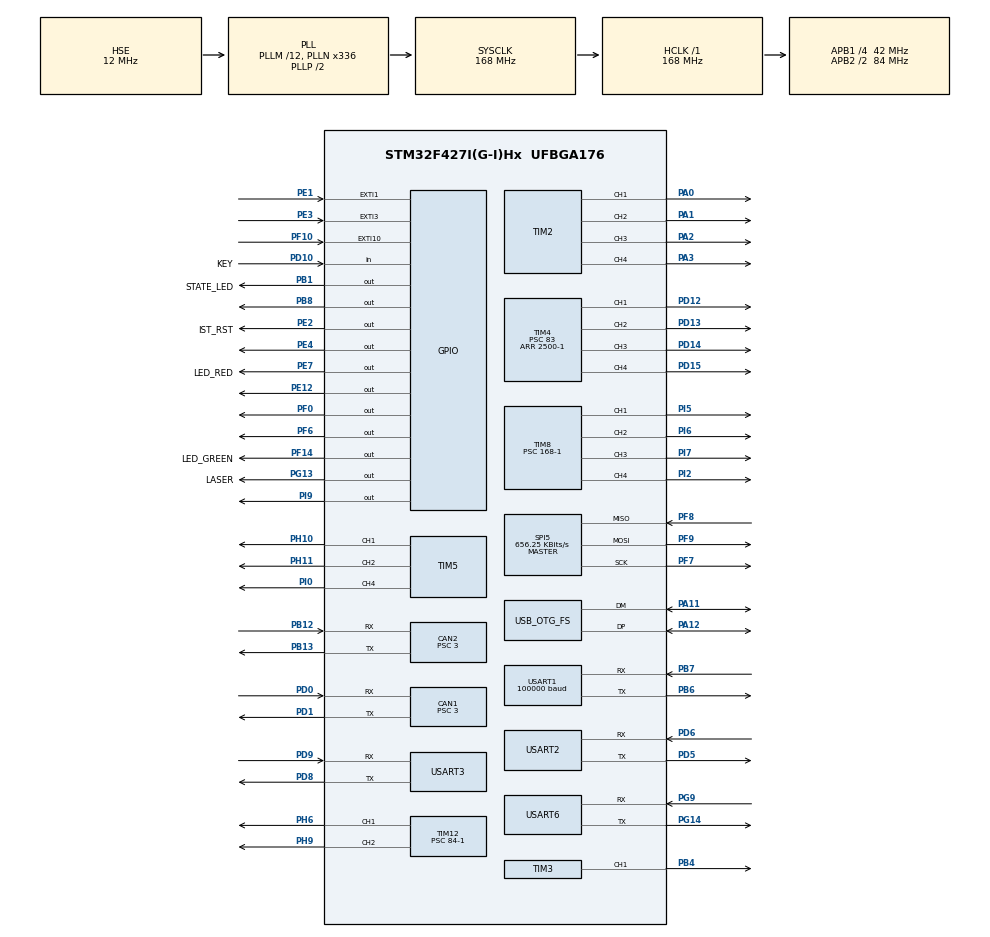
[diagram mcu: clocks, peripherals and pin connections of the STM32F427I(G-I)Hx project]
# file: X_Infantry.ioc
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CAN1.ABOM=DISABLE
CAN1.BS1=CAN_BS1_9TQ
CAN1.BS2=CAN_BS2_4TQ
CAN1.CalculateTimeBit=1000
CAN1.CalculateTimeQuantum=71.42857142857143
CAN1.Mode=CAN_MODE_NORMAL
CAN1.Prescaler=3
CAN1.SJW=CAN_SJW_1TQ
CAN1.TXFP=DISABLE
CAN2.ABOM=DISABLE
CAN2.BS1=CAN_BS1_9TQ
CAN2.BS2=CAN_BS2_4TQ
CAN2.CalculateTimeBit=1000
CAN2.CalculateTimeQuantum=71.42857142857143
CAN2.Mode=CAN_MODE_NORMAL
CAN2.Prescaler=3
CAN2.TXFP=DISABLE
Dma.Request0=USART1_RX
Dma.Request1=USART3_RX
Dma.USART1_RX.0.Direction=DMA_PERIPH_TO_MEMORY
Dma.USART1_RX.0.FIFOMode=DMA_FIFOMODE_DISABLE
Dma.USART1_RX.0.Instance=DMA2_Stream2
Dma.USART1_RX.0.MemDataAlignment=DMA_MDATAALIGN_BYTE
Dma.USART1_RX.0.MemInc=DMA_MINC_ENABLE
Dma.USART1_RX.0.Mode=DMA_NORMAL
Dma.USART1_RX.0.PeriphDataAlignment=DMA_PDATAALIGN_BYTE
Dma.USART1_RX.0.PeriphInc=DMA_PINC_DISABLE
Dma.USART1_RX.0.Priority=DMA_PRIORITY_LOW
Dma.USART3_RX.1.Direction=DMA_PERIPH_TO_MEMORY
Dma.USART3_RX.1.FIFOMode=DMA_FIFOMODE_DISABLE
Dma.USART3_RX.1.Instance=DMA1_Stream1
Dma.USART3_RX.1.MemDataAlignment=DMA_MDATAALIGN_BYTE
Dma.USART3_RX.1.MemInc=DMA_MINC_ENABLE
Dma.USART3_RX.1.Mode=DMA_NORMAL
Dma.USART3_RX.1.PeriphDataAlignment=DMA_PDATAALIGN_BYTE
Dma.USART3_RX.1.PeriphInc=DMA_PINC_DISABLE
Dma.USART3_RX.1.Priority=DMA_PRIORITY_LOW
FREERTOS.Tasks01=defaultTask,0,128,StartDefaultTask,Default,NULL
FREERTOS.configTOTAL_HEAP_SIZE=50000
IWDG.Prescaler=IWDG_PRESCALER_64
IWDG.Reload=2000
Mcu.Family=STM32F4
Mcu.Name=STM32F427I(G-I)Hx
Mcu.Package=UFBGA176
NVIC.CAN1_RX0_IRQn=true\:5\:0\:true\:false\:true\:true
NVIC.CAN1_TX_IRQn=true\:5\:0\:true\:false\:true\:true
NVIC.CAN2_RX0_IRQn=true\:5\:0\:true\:false\:true\:true
NVIC.CAN2_TX_IRQn=true\:5\:0\:true\:false\:true\:true
NVIC.DMA1_Stream1_IRQn=true\:5\:0\:false\:false\:true\:true
NVIC.DMA2_Stream2_IRQn=true\:5\:0\:false\:false\:true\:true
NVIC.EXTI15_10_IRQn=true\:5\:0\:false\:false\:true\:true
NVIC.EXTI1_IRQn=true\:5\:0\:false\:false\:true\:true
NVIC.EXTI3_IRQn=true\:5\:0\:false\:false\:true\:true
NVIC.OTG_FS_IRQn=true\:5\:0\:true\:false\:true\:true
NVIC.PriorityGroup=NVIC_PRIORITYGROUP_4
NVIC.TIM6_DAC_IRQn=true\:5\:0\:false\:false\:true\:true
NVIC.USART1_IRQn=true\:5\:0\:false\:false\:true\:true
NVIC.USART2_IRQn=true\:5\:0\:true\:false\:true\:true
NVIC.USART3_IRQn=true\:5\:0\:true\:false\:true\:true
NVIC.USART6_IRQn=true\:5\:0\:true\:false\:true\:true
PA0/WKUP.Signal=S_TIM2_CH1_ETR
PA1.Signal=S_TIM2_CH2
PA11.Mode=Device_Only
PA11.Signal=USB_OTG_FS_DM
PA12.GPIO_PuPd=GPIO_PULLUP
PA12.Mode=Device_Only
PA12.Signal=USB_OTG_FS_DP
PA13.Mode=Serial_Wire
PA13.Signal=SYS_JTMS-SWDIO
PA14.Mode=Serial_Wire
PA14.Signal=SYS_JTCK-SWCLK
PA2.Signal=S_TIM2_CH3
PA3.Signal=S_TIM2_CH4
PB1.GPIO_Label=STATE_LED
PB1.Signal=GPIO_Output
PB12.Mode=Slave
PB12.Signal=CAN2_RX
PB13.Mode=Slave
PB13.Signal=CAN2_TX
PB4.Signal=S_TIM3_CH1
PB6.Mode=Asynchronous
PB6.Signal=USART1_TX
PB7.Mode=Asynchronous
PB7.Signal=USART1_RX
PB8.GPIO_Speed=GPIO_SPEED_FREQ_MEDIUM
PB8.Signal=GPIO_Output
PD0.Mode=Master
PD0.Signal=CAN1_RX
PD1.Mode=Master
PD1.Signal=CAN1_TX
PD10.GPIO_Label=KEY
PD10.Signal=GPIO_Input
PD12.Signal=S_TIM4_CH1
PD13.Signal=S_TIM4_CH2
PD14.Signal=S_TIM4_CH3
PD15.Signal=S_TIM4_CH4
PD5.Mode=Multiprocessor_communication
PD5.Signal=USART2_TX
PD6.Mode=Multiprocessor_communication
PD6.Signal=USART2_RX
PD8.Mode=Multiprocessor_communication
PD8.Signal=USART3_TX
PD9.Mode=Multiprocessor_communication
PD9.Signal=USART3_RX
PE1.GPIO_ModeDefaultEXTI=GPIO_MODE_IT_RISING_FALLING
PE1.GPIO_PuPd=GPIO_NOPULL
PE1.Signal=GPXTI1
PE12.GPIO_Speed=GPIO_SPEED_FREQ_MEDIUM
PE12.Signal=GPIO_Output
PE2.GPIO_Label=IST_RST
PE2.GPIO_Speed=GPIO_SPEED_FREQ_VERY_HIGH
PE2.Signal=GPIO_Output
PE3.GPIO_ModeDefaultEXTI=GPIO_MODE_IT_RISING_FALLING
PE3.GPIO_PuPd=GPIO_NOPULL
PE3.Signal=GPXTI3
PE4.GPIO_Speed=GPIO_SPEED_FREQ_MEDIUM
PE4.Signal=GPIO_Output
PE7.GPIO_Label=LED_RED
PE7.Signal=GPIO_Output
PF0.GPIO_Speed=GPIO_SPEED_FREQ_MEDIUM
PF0.Signal=GPIO_Output
PF10.GPIO_ModeDefaultEXTI=GPIO_MODE_IT_RISING_FALLING
PF10.Signal=GPXTI10
PF14.GPIO_Label=LED_GREEN
PF14.Signal=GPIO_Output
PF6.GPIO_Speed=GPIO_SPEED_FREQ_VERY_HIGH
PF6.PinState=GPIO_PIN_RESET
PF6.Signal=GPIO_Output
PF7.Mode=Full_Duplex_Master
PF7.Signal=SPI5_SCK
PF8.Mode=Full_Duplex_Master
PF8.Signal=SPI5_MISO
PF9.Mode=Full_Duplex_Master
PF9.Signal=SPI5_MOSI
PG13.GPIO_Label=LASER
PG13.Signal=GPIO_Output
PG14.Mode=Multiprocessor_communication
PG14.Signal=USART6_TX
PG9.Mode=Multiprocessor_communication
PG9.Signal=USART6_RX
PH0/OSC_IN.Mode=HSE-External-Oscillator
PH0/OSC_IN.Signal=RCC_OSC_IN
PH1/OSC_OUT.Mode=HSE-External-Oscillator
PH1/OSC_OUT.Signal=RCC_OSC_OUT
PH10.Signal=S_TIM5_CH1
PH11.Signal=S_TIM5_CH2
PH6.Signal=S_TIM12_CH1
PH9.Signal=S_TIM12_CH2
PI0.Signal=S_TIM5_CH4
PI2.Signal=S_TIM8_CH4
PI5.Signal=S_TIM8_CH1
PI6.Signal=S_TIM8_CH2
PI7.Signal=S_TIM8_CH3
PI9.GPIO_Speed=GPIO_SPEED_FREQ_MEDIUM
PI9.Signal=GPIO_Output
ProjectManager.HeapSize=0x1000
ProjectManager.StackSize=0x400
ProjectManager.TargetToolchain=MDK-ARM V5
RCC.48MHZClocksFreq_Value=48000000
RCC.AHBFreq_Value=168000000
RCC.APB1CLKDivider=RCC_HCLK_DIV4
RCC.APB1Freq_Value=42000000
RCC.APB1TimFreq_Value=84000000
RCC.APB2CLKDivider=RCC_HCLK_DIV2
RCC.APB2Freq_Value=84000000
RCC.APB2TimFreq_Value=168000000
RCC.CortexFreq_Value=168000000
RCC.HCLKFreq_Value=168000000
RCC.HSE_VALUE=12000000
RCC.HSI_VALUE=16000000
RCC.LSE_VALUE=32768
RCC.PLLM=12
RCC.PLLN=336
RCC.PLLQ=7
RCC.SYSCLKFreq_VALUE=168000000
RCC.SYSCLKSource=RCC_SYSCLKSOURCE_PLLCLK
RCC.VCOOutputFreq_Value=336000000
SH.S_TIM12_CH1.0=TIM12_CH1,PWM Generation1 CH1
SH.S_TIM12_CH2.0=TIM12_CH2,PWM Generation2 CH2
SH.S_TIM2_CH1_ETR.0=TIM2_CH1,PWM Generation1 CH1
SH.S_TIM2_CH2.0=TIM2_CH2,PWM Generation2 CH2
SH.S_TIM2_CH3.0=TIM2_CH3,PWM Generation3 CH3
SH.S_TIM2_CH4.0=TIM2_CH4,PWM Generation4 CH4
SH.S_TIM3_CH1.0=TIM3_CH1,PWM Generation1 CH1
SH.S_TIM4_CH1.0=TIM4_CH1,PWM Generation1 CH1
SH.S_TIM4_CH2.0=TIM4_CH2,PWM Generation2 CH2
SH.S_TIM4_CH3.0=TIM4_CH3,PWM Generation3 CH3
SH.S_TIM4_CH4.0=TIM4_CH4,PWM Generation4 CH4
SH.S_TIM5_CH1.0=TIM5_CH1,PWM Generation1 CH1
SH.S_TIM5_CH2.0=TIM5_CH2,PWM Generation2 CH2
SH.S_TIM5_CH4.0=TIM5_CH4,PWM Generation4 CH4
SH.S_TIM8_CH1.0=TIM8_CH1,PWM Generation1 CH1
SH.S_TIM8_CH2.0=TIM8_CH2,PWM Generation2 CH2
SH.S_TIM8_CH3.0=TIM8_CH3,PWM Generation3 CH3
SH.S_TIM8_CH4.0=TIM8_CH4,PWM Generation4 CH4
SPI5.BaudRatePrescaler=SPI_BAUDRATEPRESCALER_128
SPI5.CalculateBaudRate=656.25 KBits/s
SPI5.Direction=SPI_DIRECTION_2LINES
SPI5.Mode=SPI_MODE_MASTER
SPI5.VirtualType=VM_MASTER
TIM12.Channel-PWM\ Generation1\ CH1=TIM_CHANNEL_1
TIM12.Channel-PWM\ Generation2\ CH2=TIM_CHANNEL_2
TIM12.Period=2500-1
TIM12.Prescaler=84-1
TIM12.Pulse-PWM\ Generation1\ CH1=1000
TIM12.Pulse-PWM\ Generation2\ CH2=1000
TIM2.Channel-PWM\ Generation1\ CH1=TIM_CHANNEL_1
TIM2.Channel-PWM\ Generation2\ CH2=TIM_CHANNEL_2
TIM2.Channel-PWM\ Generation3\ CH3=TIM_CHANNEL_3
TIM2.Channel-PWM\ Generation4\ CH4=TIM_CHANNEL_4
TIM3.Channel-PWM\ Generation1\ CH1=TIM_CHANNEL_1
TIM3.Period=1000
TIM3.Prescaler=84-1
TIM4.Channel-PWM\ Generation1\ CH1=TIM_CHANNEL_1
TIM4.Channel-PWM\ Generation2\ CH2=TIM_CHANNEL_2
TIM4.Channel-PWM\ Generation3\ CH3=TIM_CHANNEL_3
TIM4.Channel-PWM\ Generation4\ CH4=TIM_CHANNEL_4
TIM4.Period=2500-1
TIM4.Prescaler=83
TIM4.Pulse-PWM\ Generation1\ CH1=1000
TIM4.Pulse-PWM\ Generation2\ CH2=1000
TIM4.Pulse-PWM\ Generation3\ CH3=1000
TIM5.Channel-PWM\ Generation1\ CH1=TIM_CHANNEL_1
TIM5.Channel-PWM\ Generation2\ CH2=TIM_CHANNEL_2
TIM5.Channel-PWM\ Generation4\ CH4=TIM_CHANNEL_4
TIM6.Period=0xffff
TIM6.Prescaler=84-1
TIM8.Channel-PWM\ Generation1\ CH1=TIM_CHANNEL_1
TIM8.Channel-PWM\ Generation2\ CH2=TIM_CHANNEL_2
TIM8.Channel-PWM\ Generation3\ CH3=TIM_CHANNEL_3
TIM8.Channel-PWM\ Generation4\ CH4=TIM_CHANNEL_4
TIM8.Prescaler=168-1
USART1.BaudRate=100000
USART1.Mode=MODE_RX
USART1.Parity=PARITY_EVEN
USART1.VirtualMode=VM_ASYNC
USART1.WordLength=WORDLENGTH_9B
USART2.VirtualMode=VM_ASYNC
USART3.VirtualMode=VM_ASYNC
USART6.VirtualMode=VM_ASYNC
USB_DEVICE.CLASS_NAME_FS=CDC
USB_DEVICE.USBD_CDC_INTERVAL-CDC_FS=5
USB_DEVICE.USBD_HandleTypeDef-CDC_FS=hUsbDeviceFS
USB_DEVICE.USBD_MAX_STR_DESC_SIZ-CDC_FS=128
USB_DEVICE.VirtualMode-CDC_FS=Cdc
USB_DEVICE.VirtualModeFS=Cdc_FS
USB_OTG_FS.VirtualMode=Device_Only
USB_OTG_FS.vbus_sensing_enable=DISABLE
VP_FREERTOS_VS_ENABLE.Mode=Enabled
VP_IWDG_VS_IWDG.Mode=IWDG_Activate
VP_TIM12_VS_ClockSourceINT.Mode=Internal
VP_TIM2_VS_ClockSourceINT.Mode=Internal
VP_TIM3_VS_ClockSourceINT.Mode=Internal
VP_TIM4_VS_ClockSourceINT.Mode=Internal
VP_TIM5_VS_ClockSourceINT.Mode=Internal
VP_TIM6_VS_ClockSourceINT.Mode=Enable_Timer
VP_TIM8_VS_ClockSourceINT.Mode=Internal
VP_USB_DEVICE_VS_USB_DEVICE_CDC_FS.Mode=CDC_FS
board=X_Infantry

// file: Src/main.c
/**
  ******************************************************************************
  * File Name          : main.c
  * Description        : Main program body
  ******************************************************************************
  *
  * Copyright (c) 2017 STMicroelectronics International N.V.
  * All rights reserved.
  *
  * Redistribution and use in source and binary forms, with or without
  * modification, are permitted, provided that the following conditions are met:
  *
  * 1. Redistribution of source code must retain the above copyright notice,
  *    this list of conditions and the following disclaimer.
  * 2. Redistributions in binary form must reproduce the above copyright notice,
  *    this list of conditions and the following disclaimer in the documentation
  *    and/or other materials provided with the distribution.
  * 3. Neither the name of STMicroelectronics nor the names of other
  *    contributors to this software may be used to endorse or promote products
  *    derived from this software without specific written permission.
  * 4. This software, including modifications and/or derivative works of this
  *    software, must execute solely and exclusively on microcontroller or
  *    microprocessor devices manufactured by or for STMicroelectronics.
  * 5. Redistribution and use of this software other than as permitted under
  *    this license is void and will automatically terminate your rights under
  *    this license.
  *
  * THIS SOFTWARE IS PROVIDED BY STMICROELECTRONICS AND CONTRIBUTORS "AS IS"
  * AND ANY EXPRESS, IMPLIED OR STATUTORY WARRANTIES, INCLUDING, BUT NOT
  * LIMITED TO, THE IMPLIED WARRANTIES OF MERCHANTABILITY, FITNESS FOR A
  * PARTICULAR PURPOSE AND NON-INFRINGEMENT OF THIRD PARTY INTELLECTUAL PROPERTY
  * RIGHTS ARE DISCLAIMED TO THE FULLEST EXTENT PERMITTED BY LAW. IN NO EVENT
  * SHALL STMICROELECTRONICS OR CONTRIBUTORS BE LIABLE FOR ANY DIRECT, INDIRECT,
  * INCIDENTAL, SPECIAL, EXEMPLARY, OR CONSEQUENTIAL DAMAGES (INCLUDING, BUT NOT
  * LIMITED TO, PROCUREMENT OF SUBSTITUTE GOODS OR SERVICES; LOSS OF USE, DATA,
  * OR PROFITS; OR BUSINESS INTERRUPTION) HOWEVER CAUSED AND ON ANY THEORY OF
  * LIABILITY, WHETHER IN CONTRACT, STRICT LIABILITY, OR TORT (INCLUDING
  * NEGLIGENCE OR OTHERWISE) ARISING IN ANY WAY OUT OF THE USE OF THIS SOFTWARE,
  * EVEN IF ADVISED OF THE POSSIBILITY OF SUCH DAMAGE.
  *
  ******************************************************************************
  */
#include "main.h"
#include "stm32f4xx_hal.h"
#include "cmsis_os.h"
#include "can.h"
#include "dma.h"
#include "iwdg.h"
#include "spi.h"
#include "tim.h"
#include "usart.h"
#include "usb_device.h"
#include "gpio.h"

/* USER CODE BEGIN Includes */
#include "utilities_debug.h"
#include "stm32f4xx_hal_iwdg.h"
/* USER CODE END Includes */

/* USER CODE BEGIN PV */
/* Private variables ---------------------------------------------------------*/
uint32_t ADC_Value[140];
/* USER CODE END PV */

void SystemClock_Config(void);
void Error_Handler(void);
void MX_FREERTOS_Init(void);

/* USER CODE BEGIN PFP */
/* Private function prototypes -----------------------------------------------*/

/* USER CODE END PFP */

int main(void)
{

  /* MCU Configuration----------------------------------------------------------*/

  /* Reset of all peripherals, Initializes the Flash interface and the Systick. */
  HAL_Init();

  /* Configure the system clock */
  SystemClock_Config();

  /* Initialize all configured peripherals */
  MX_GPIO_Init();
  MX_DMA_Init();
  MX_CAN1_Init();
  MX_CAN2_Init();
  MX_SPI5_Init();
  MX_TIM2_Init();
  MX_TIM4_Init();
  MX_TIM5_Init();
  MX_TIM6_Init();
  MX_TIM8_Init();
  MX_TIM12_Init();
  MX_USART2_UART_Init();
  MX_USART3_UART_Init();
  MX_USART6_UART_Init();
  MX_TIM3_Init();
  MX_USART1_UART_Init();
  //MX_IWDG_Init();

  /* USER CODE BEGIN 2 */
	//__HAL_IWDG_START(&hiwdg);
  /* USER CODE END 2 */

  /* Call init function for freertos objects (in freertos.c) */
  MX_FREERTOS_Init();

  /* Start scheduler */
  osKernelStart();

  /* We should never get here as control is now taken by the scheduler */

  /* Infinite loop */
  while (1)
  {

  }

}

/** System Clock Configuration
*/
void SystemClock_Config(void)
{

  RCC_OscInitTypeDef RCC_OscInitStruct;
  RCC_ClkInitTypeDef RCC_ClkInitStruct;

    /**Configure the main internal regulator output voltage
    */
  __HAL_RCC_PWR_CLK_ENABLE();

  __HAL_PWR_VOLTAGESCALING_CONFIG(PWR_REGULATOR_VOLTAGE_SCALE1);

    /**Initializes the CPU, AHB and APB busses clocks
    */
  RCC_OscInitStruct.OscillatorType = RCC_OSCILLATORTYPE_LSI|RCC_OSCILLATORTYPE_HSE;
  RCC_OscInitStruct.HSEState = RCC_HSE_ON;
  RCC_OscInitStruct.LSIState = RCC_LSI_ON;
  RCC_OscInitStruct.PLL.PLLState = RCC_PLL_ON;
  RCC_OscInitStruct.PLL.PLLSource = RCC_PLLSOURCE_HSE;
  RCC_OscInitStruct.PLL.PLLM = 12;
  RCC_OscInitStruct.PLL.PLLN = 336;
  RCC_OscInitStruct.PLL.PLLP = RCC_PLLP_DIV2;
  RCC_OscInitStruct.PLL.PLLQ = 7;
  if (HAL_RCC_OscConfig(&RCC_OscInitStruct) != HAL_OK)
  {
    Error_Handler();
  }

    /**Initializes the CPU, AHB and APB busses clocks
    */
  RCC_ClkInitStruct.ClockType = RCC_CLOCKTYPE_HCLK|RCC_CLOCKTYPE_SYSCLK
                              |RCC_CLOCKTYPE_PCLK1|RCC_CLOCKTYPE_PCLK2;
  RCC_ClkInitStruct.SYSCLKSource = RCC_SYSCLKSOURCE_PLLCLK;
  RCC_ClkInitStruct.AHBCLKDivider = RCC_SYSCLK_DIV1;
  RCC_ClkInitStruct.APB1CLKDivider = RCC_HCLK_DIV4;
  RCC_ClkInitStruct.APB2CLKDivider = RCC_HCLK_DIV2;

  if (HAL_RCC_ClockConfig(&RCC_ClkInitStruct, FLASH_LATENCY_5) != HAL_OK)
  {
    Error_Handler();
  }

    /**Configure the Systick interrupt time
    */
  HAL_SYSTICK_Config(HAL_RCC_GetHCLKFreq()/1000);

    /**Configure the Systick
    */
  HAL_SYSTICK_CLKSourceConfig(SYSTICK_CLKSOURCE_HCLK);

  /* SysTick_IRQn interrupt configuration */
  HAL_NVIC_SetPriority(SysTick_IRQn, 15, 0);
}

void Error_Handler(void)
{
  /* USER CODE BEGIN Error_Handler */
  /* User can add his own implementation to report the HAL error return state */
  while(1)
  {
		fw_printfln("ERROR HANDLE");
 		uint16_t delayTime = 1000;
 		for(uint16_t i = 0; i < delayTime; i++)
 		{
 			uint16_t a = 42000; //at 168MHz 42000 is ok
 			while(a--);
 		}
  }
  /* USER CODE END Error_Handler */
}

/************************ (C) COPYRIGHT STMicroelectronics *****END OF FILE****/
